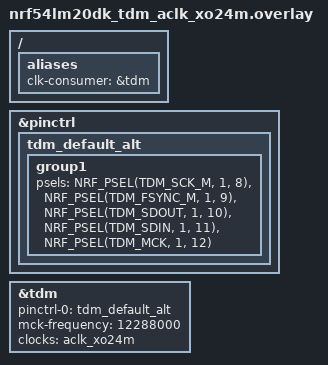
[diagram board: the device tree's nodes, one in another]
/*
 * TDM case 1: SCK and MCK both on the 24 MHz audio clock (ACLK), sourced from the HFXO via XO24M.
 *
 * A single clock state is given, so it applies to both SCK and MCK. The aclk_xo24m state maps to
 * the ACLK mux position and names the xo24m producer, which the TDM driver requests (through one
 * client per signal, i.e. twice here for the same producer, balanced by two releases).
 */
/ {
	aliases {
		clk-consumer = &tdm;
	};
};

&pinctrl {
	tdm_default_alt: tdm_default_alt {
		group1 {
			psels = <NRF_PSEL(TDM_SCK_M, 1, 8)>,
				<NRF_PSEL(TDM_FSYNC_M, 1, 9)>,
				<NRF_PSEL(TDM_SDOUT, 1, 10)>,
				<NRF_PSEL(TDM_SDIN, 1, 11)>,
				<NRF_PSEL(TDM_MCK, 1, 12)>;
		};
	};
};

&tdm {
	status = "okay";
	pinctrl-0 = <&tdm_default_alt>;
	pinctrl-names = "default";
	mck-frequency = <12288000>;
	clocks = <&aclk_xo24m>;
};
